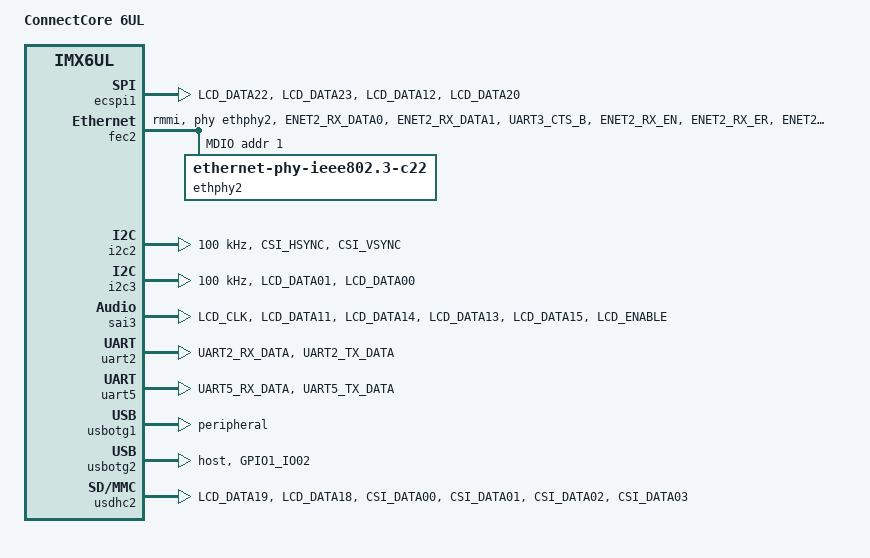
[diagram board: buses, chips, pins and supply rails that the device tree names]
/*
 * Device tree generated automatically by Digi ConnectCore Smart IOmux.
 *
 * This file is provided "AS IS" without any warranties and support.
 * Please verify the pin assignation with the hardware reference manual.
 */

/dts-v1/;
#include <dt-bindings/input/input.h>
/* i.MX6 UltraLite CPU */
#include "imx6ul.dtsi"

/ {
    // Add here your platform model.
    model = "ConnectCore 6UL";
    // Add here your compatible platform.
    compatible = "digi,ccimx6ul", "fsl,imx6ul";

    /*
     * Reference block.
     *
     * Add your sensor configuration.
     */
    //sound_max98089: sound-max98089 {
    //  compatible = "fsl,imx-audio-max98088";
    //  model = "imx-max98088";
    //  cpu-dai = <&sai3>;
    //  audio-codec = <&max98089>;
    //  asrc-controller = <&asrc>;
    //  gpr = <&gpr>;
    //  audio-routing =
    //      "Headphone Jack", "HPL",
    //      "Headphone Jack", "HPR",
    //      "Ext Spk", "SPKL",
    //      "Ext Spk", "SPKR",
    //      "LineOut", "RECL",
    //      "LineOut", "RECR",
    //      "Mic1", "MIC1",
    //      "Mic2", "MIC2",
    //      "LineInA", "INA1",
    //      "LineInA", "INA2",
    //      "LineInB", "INB1",
    //      "LineInB", "INB2";
    //  status = "okay";
    //};
};

// &can1 {
//     pinctrl-names = "default";
//     pinctrl-0 = <&pinctrl_flexcan1>;

//     /*
//      * Optional field.
//      *
//      * Set the proper voltage regulator to power the
//      * transceiver if needed.
//      */
//     xceiver-supply = <&ext_3v3>;

//     status = "okay";
// };

&ecspi1 {
    fsl,spi-num-chipselects = <1>;
    pinctrl-names = "default";
    status = "okay";

    /*
     * Configure the GPIO that you selected as 'slave select'.
     */
    //cs-gpios = <&gpio3 26 GPIO_ACTIVE_LOW>;

    /*
     * ECSPI1 (as master)
     */
    pinctrl-0 = <&pinctrl_ecspi1>;

    /*
     * Reference block.
     *
     * Add your slave devices here. Next is an example of spidev.
     * Expect a harmless kernel warning if you enable spidev as slave.
     */
    //spidev@0 {
    //    reg = <0>;
    //    compatible = "spidev";
    //    spi-max-frequency = <1000000>;
    //};

};

&fec2 {
    pinctrl-names = "default";
    pinctrl-0 = <&pinctrl_enet2 &pinctrl_enet_mdio>;
    phy-mode = "rmmi";
    phy-handle = <&ethphy2>;

    /*
     * Optional fields.
     *
     * Configure the phy reset with a GPIO in your design.
     */
    //phy-reset-gpios = <&gpio5 6 GPIO_ACTIVE_LOW>
    //phy-reset-duration = <26>;
    //digi,phy-reset-in-suspend;

    status = "okay";

    mdio {
        #address-cells = <1>;
        #size-cells = <0>;

        ethphy2: ethernet-phy@1 {
            compatible = "ethernet-phy-ieee802.3-c22";

            /*
             * Add your custom PHY configuration.
             */
            //smsc,disable-energy-detect;

            reg = <1>;
        };
    };
};

&i2c2 {
    clock-frequency = <100000>;
    pinctrl-names = "default";
    pinctrl-0 = <&pinctrl_i2c2>;
    status = "okay";

    /*
     * Reference block.
     *
     * Add the peripherals connected to the I2C.
     */
    //fusion_touch: fusion@14 {
    //  compatible = "touchrev,fusion-touch";
    //  reg = <0x14>;
    //  pinctrl-names = "default";
    //  pinctrl-0 = <&pinctrl_fusion_touch>;
    //  interrupt-parent = <&gpio5>;
    //  interrupts = <2 IRQ_TYPE_EDGE_RISING>;
    //  status = "disabled";
    //};
};

&i2c3 {
    clock-frequency = <100000>;
    pinctrl-names = "default";
    pinctrl-0 = <&pinctrl_i2c3>;
    status = "okay";

    /*
     * Reference block.
     *
     * Add the peripherals connected to the I2C.
     */
    //fusion_touch: fusion@14 {
    //  compatible = "touchrev,fusion-touch";
    //  reg = <0x14>;
    //  pinctrl-names = "default";
    //  pinctrl-0 = <&pinctrl_fusion_touch>;
    //  interrupt-parent = <&gpio5>;
    //  interrupts = <2 IRQ_TYPE_EDGE_RISING>;
    //  status = "disabled";
    //};
};

&sai3 {
    pinctrl-names = "default";
    pinctrl-0 = <&pinctrl_sai3>;

    /*
     * Reference block.
     *
     * Codec dependent section.
     */
    //assigned-clocks = <&clks IMX6UL_CLK_SAI3_SEL>,
    //        <&clks IMX6UL_CLK_PLL4_AUDIO_DIV>,
    //        <&clks IMX6UL_CLK_SAI3>;
    //assigned-clock-rates = <0>, <786432000>, <12288000>;
    //assigned-clock-parents = <&clks IMX6UL_CLK_PLL4_AUDIO_DIV>;

    status = "okay";
};

&uart2 {
    pinctrl-names = "default";
    pinctrl-0 = <&pinctrl_uart2>;

    status = "okay";
};

&uart5 {
    pinctrl-names = "default";
    pinctrl-0 = <&pinctrl_console>;
    status = "okay";
};

&usbotg1 {
    dr_mode = "peripheral";

    /*
     * Set the proper voltage regulator to power the
     * vbus if needed.
     */
    //vbus-supply = <&reg_usb_otg1_vbus>;

    status = "okay";
};

&usbotg2 {
    dr_mode = "host";

    /*
     * Set the proper voltage regulator to power the
     * vbus if needed.
     */
    //vbus-supply = <&reg_usb_otg1_vbus>;

    /*
     * Configure the power line if needed.
     */
    //fsl,power-line-polarity-active-high;

    /*
     * Configure the overcurrent line if needed.
     */
    //fsl,over-current-polarity-active-low;
    //disable-over-current;

    pinctrl-0 = <&pinctrl_usbotg2>;

    status = "okay";
};

&usdhc2 {
    pinctrl-names = "default";
    pinctrl-0 = <&pinctrl_usdhc2>;
    no-1-8-v;
    status = "okay";
};

&iomuxc {
    pinctrl-0 = <&pinctrl_hog>;

    imx6ul-ccimx6ul {
        pinctrl_console: uart5grp {
            fsl,pins = <
                MX6UL_PAD_UART5_RX_DATA__UART5_DCE_RX		0x1b0b1
                MX6UL_PAD_UART5_TX_DATA__UART5_DCE_TX		0x1b0b1
            >;
        };

        pinctrl_ecspi1: ecspi1grp1 {
            fsl,pins = <
                MX6UL_PAD_LCD_DATA22__ECSPI1_MOSI		0x10b0
                MX6UL_PAD_LCD_DATA23__ECSPI1_MISO		0x10b0
                MX6UL_PAD_LCD_DATA12__ECSPI1_RDY		0x10b0
                MX6UL_PAD_LCD_DATA20__ECSPI1_SCLK		0x10b0
            >;
        };

        pinctrl_enet2: enet2grp {
            fsl,pins = <
                MX6UL_PAD_ENET2_RX_DATA0__ENET2_RDATA00		0x1b0b0
                MX6UL_PAD_ENET2_RX_DATA1__ENET2_RDATA01		0x1b0b0
                MX6UL_PAD_UART3_CTS_B__ENET2_RX_CLK		0x40017051
                MX6UL_PAD_ENET2_RX_EN__ENET2_RX_EN		0x1b0b0
                MX6UL_PAD_ENET2_RX_ER__ENET2_RX_ER		0x1b0b0
                MX6UL_PAD_ENET2_TX_DATA0__ENET2_TDATA00		0x1b0b0
                MX6UL_PAD_ENET2_TX_DATA1__ENET2_TDATA01		0x1b0b0
                MX6UL_PAD_ENET2_TX_CLK__ENET2_TX_CLK		0x40017051
                MX6UL_PAD_ENET2_TX_EN__ENET2_TX_EN		0x1b0b0
                MX6UL_PAD_UART3_RTS_B__ENET2_TX_ER		0x1b0b0
            >;
        };

        pinctrl_enet_mdio: mdioenetgrp {
            fsl,pins = <
                MX6UL_PAD_GPIO1_IO07__ENET2_MDC		0x1b0b0
                MX6UL_PAD_GPIO1_IO06__ENET2_MDIO		0x1b0b0
            >;
        };

        pinctrl_flexcan1: flexcan1grp {
            fsl,pins = <
                MX6UL_PAD_ENET1_RX_DATA1__FLEXCAN1_RX		0x1b020
                MX6UL_PAD_ENET1_RX_DATA0__FLEXCAN1_TX		0x1b020
            >;
        };

        pinctrl_hog: hoggrp {
            fsl,pins = <
                /* gpio_id_0 */
                MX6UL_PAD_GPIO1_IO05__GPIO1_IO05		0x10b0
                /* gpio_id_1 */
                MX6UL_PAD_GPIO1_IO08__GPIO1_IO08		0x10b0
                /* gpio_id_2 */
                MX6UL_PAD_GPIO1_IO09__GPIO1_IO09		0x10b0
                /* gpio_id_3 */
                MX6UL_PAD_SNVS_TAMPER1__GPIO5_IO01		0x10b0
                /* gpio_id_4 */
                MX6UL_PAD_SNVS_TAMPER2__GPIO5_IO02		0x10b0
                /* gpio_id_5 */
                MX6UL_PAD_SNVS_TAMPER5__GPIO5_IO05		0x10b0
                /* gpio_id_6 */
                MX6UL_PAD_SNVS_TAMPER6__GPIO5_IO06		0x10b0
                /* gpio_id_7 */
                MX6UL_PAD_SNVS_TAMPER7__GPIO5_IO07		0x10b0
                /* gpio_id_8 */
                MX6UL_PAD_SNVS_TAMPER8__GPIO5_IO08		0x10b0
                /* gpio_id_9 */
                MX6UL_PAD_GPIO1_IO03__GPIO1_IO03		0x10b0
                /* gpio_id_10 */
                MX6UL_PAD_LCD_DATA21__GPIO3_IO26		0x10b0
                /* gpio_id_11 */
                MX6UL_PAD_GPIO1_IO00__GPIO1_IO00		0x10b0
                /* gpio_id_12 */
                MX6UL_PAD_GPIO1_IO01__GPIO1_IO01		0x10b0
                /* gpio_id_13 */
                MX6UL_PAD_GPIO1_IO04__GPIO1_IO04		0x10b0
                /* gpio_id_14 */
                MX6UL_PAD_JTAG_MOD__GPIO1_IO10		0x10b0
                /* gpio_id_15 */
                MX6UL_PAD_JTAG_TMS__GPIO1_IO11		0x10b0
                /* gpio_id_16 */
                MX6UL_PAD_JTAG_TDO__GPIO1_IO12		0x10b0
                /* gpio_id_17 */
                MX6UL_PAD_JTAG_TDI__GPIO1_IO13		0x10b0
                /* gpio_id_18 */
                MX6UL_PAD_JTAG_TCK__GPIO1_IO14		0x10b0
                /* gpio_id_19 */
                MX6UL_PAD_JTAG_TRST_B__GPIO1_IO15		0x10b0
                /* gpio_id_20 */
                MX6UL_PAD_UART2_CTS_B__GPIO1_IO22		0x10b0
            >;
        };

        pinctrl_i2c2: i2c2grp {
            fsl,pins = <
                MX6UL_PAD_CSI_HSYNC__I2C2_SCL		0x4001b8b0
                MX6UL_PAD_CSI_VSYNC__I2C2_SDA		0x4001b8b0
            >;
        };

        pinctrl_i2c3: i2c3grp {
            fsl,pins = <
                MX6UL_PAD_LCD_DATA01__I2C3_SCL		0x4001b8b0
                MX6UL_PAD_LCD_DATA00__I2C3_SDA		0x4001b8b0
            >;
        };

        pinctrl_sai3: sai3grp {
            fsl,pins = <
                MX6UL_PAD_LCD_CLK__SAI3_MCLK		0x17088
                MX6UL_PAD_LCD_DATA11__SAI3_RX_BCLK		0x1b030
                MX6UL_PAD_LCD_DATA14__SAI3_RX_DATA		0x11088
                MX6UL_PAD_LCD_DATA13__SAI3_TX_BCLK		0x17088
                MX6UL_PAD_LCD_DATA15__SAI3_TX_DATA		0x11088
                MX6UL_PAD_LCD_ENABLE__SAI3_TX_SYNC		0x17088
            >;
        };

        pinctrl_uart2: uart2grp {
            fsl,pins = <
                MX6UL_PAD_UART2_RX_DATA__UART2_DCE_RX		0x1b0b1
                MX6UL_PAD_UART2_TX_DATA__UART2_DCE_TX		0x1b0b1
            >;
        };

        pinctrl_usbotg2: usbotg2grp {
            fsl,pins = <
                MX6UL_PAD_GPIO1_IO02__USB_OTG2_PWR		0x17059
            >;
        };

        pinctrl_usdhc2: usdhc2grp {
            fsl,pins = <
                MX6UL_PAD_LCD_DATA19__USDHC2_CLK		0x10039
                MX6UL_PAD_LCD_DATA18__USDHC2_CMD		0x17059
                MX6UL_PAD_CSI_DATA00__USDHC2_DATA0		0x17059
                MX6UL_PAD_CSI_DATA01__USDHC2_DATA1		0x17059
                MX6UL_PAD_CSI_DATA02__USDHC2_DATA2		0x17059
                MX6UL_PAD_CSI_DATA03__USDHC2_DATA3		0x17059
            >;
        };
    };
};
